# MKW01Z4 register map
File version: 1.6
Registers are 32-bit, read-write, reset 0x0 unless marked. A register's access mark holds for its fields unless they carry their own. Offsets are from the block's base; [hi:lo] are bit positions; {n}, {i} and the like mark numbered series; 'fields as' and 'values as' point back to an identical list.

## TPM0 — Timer/PWM Module
Base 0x40038000; register names take the prefix TPM0_
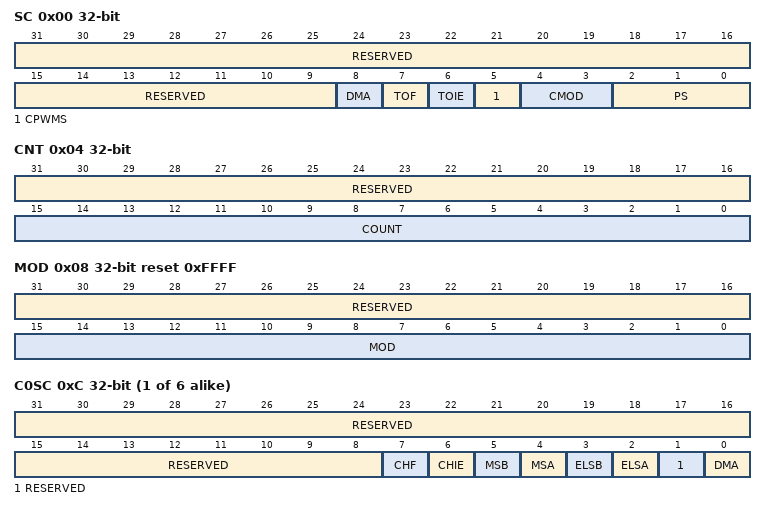
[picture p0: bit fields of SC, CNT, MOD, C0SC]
0x00 SC — Status and Control
  [31:9] RESERVED ro
  [8] DMA — DMA Enable
    0=Disables DMA transfers; 1=Enables DMA transfers
  [7] TOF — Timer Overflow Flag
    0=TPM counter has not overflowed; 1=TPM counter has overflowed
  [6] TOIE — Timer Overflow Interrupt Enable
    0=Disable TOF interrupts. Use software polling or DMA request.; 1=Enable TOF interrupts. An interrupt is generated when TOF equals one.
  [5] CPWMS — Center-Aligned PWM Select
    0=TPM counter operates in up counting mode; 1=TPM counter operates in up-down counting mode
  [4:3] CMOD — Clock Mode Selection
    0=TPM counter is disabled; 1=TPM counter increments on every TPM counter clock; 2=TPM counter increments on rising edge of TPM_EXTCLK synchronized to the TPM counter clock
  [2:0] PS — Prescale Factor Selection
    0=Divide by 1; 1=Divide by 2; 2=Divide by 4; 3=Divide by 8; 4=Divide by 16; 5=Divide by 32; 6=Divide by 64; 7=Divide by 128
0x04 CNT — Counter
  [31:16] RESERVED ro
  [15:0] COUNT — Counter value
0x08 MOD reset 0xFFFF — Modulo
  [31:16] RESERVED ro
  [15:0] MOD — Modulo value
{0xC+8i} C{i}SC (i=0..5) — Channel (n) Status and Control
  [31:8] RESERVED ro
  [7] CHF — Channel Flag
    0=No channel event has occurred; 1=A channel event has occurred
  [6] CHIE — Channel Interrupt Enable
    0=Disable channel interrupts; 1=Enable channel interrupts
  [5] MSB — Channel Mode Select
  [4] MSA — Channel Mode Select
  [3] ELSB — Edge or Level Select
  [2] ELSA — Edge or Level Select
  [1] RESERVED ro
  [0] DMA — DMA Enable
    0=Disable DMA transfers; 1=Enable DMA transfers
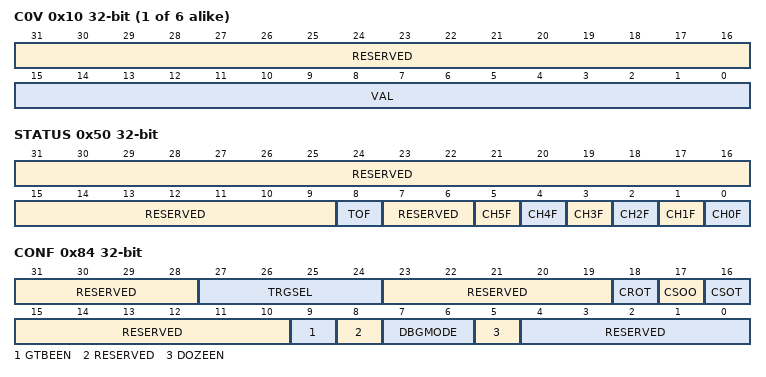
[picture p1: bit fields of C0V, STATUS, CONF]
{0x10+8i} C{i}V (i=0..5) — Channel (n) Value
  [31:16] RESERVED ro
  [15:0] VAL — Channel Value
0x50 STATUS — Capture and Compare Status
  [31:9] RESERVED ro
  [8] TOF — Timer Overflow Flag
    values as SC.TOF
  [7:6] RESERVED ro
  [n] CH{n}F (n=0..5) — Channel {n} Flag
    values as C0SC.CHF
0x84 CONF — Configuration
  [31:28] RESERVED ro
  [27:24] TRGSEL — Trigger Select
  [23:19] RESERVED ro
  [18] CROT — Counter Reload On Trigger
    0=Counter is not reloaded due to a rising edge on the selected input trigger; 1=Counter is reloaded when a rising edge is detected on the selected input trigger
  [17] CSOO — Counter Stop On Overflow
    0=TPM counter continues incrementing or decrementing after overflow; 1=TPM counter stops incrementing or decrementing after overflow
  [16] CSOT — Counter Start on Trigger
    0=TPM counter starts to increment immediately, once it is enabled; 1=TPM counter only starts to increment when it a rising edge on the selected input trigger is detected, after it has been enabled or after it has stopped due to overflow
  [15:10] RESERVED ro
  [9] GTBEEN — Global time base enable
    0=All channels use the internally generated TPM counter as their timebase; 1=All channels use an externally generated global timebase as their timebase
  [8] RESERVED ro
  [7:6] DBGMODE — Debug Mode
    0=TPM counter is paused and does not increment during debug mode. Trigger inputs and input capture events are also ignored.; 3=TPM counter continues in debug mode
  [5] DOZEEN — Doze Enable
    0=Internal TPM counter continues in Doze mode; 1=Internal TPM counter is paused and does not increment during Doze mode. Trigger inputs and input capture events are also ignored.
  [4:0] RESERVED ro

## TPM1 — Timer/PWM Module
Base 0x40039000; register names take the prefix TPM1_
Registers as TPM0, without C*SC, C*V; these are added or differ:
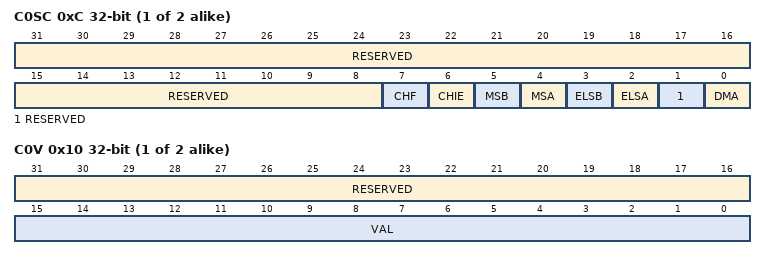
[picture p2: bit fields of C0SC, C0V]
{0xC+8i} C{i}SC (i=0..1) — Channel (n) Status and Control
  fields as TPM0.C0SC
{0x10+8i} C{i}V (i=0..1) — Channel (n) Value
  [31:16] RESERVED ro
  [15:0] VAL — Channel Value

## TPM2 — Timer/PWM Module
Base 0x4003A000; register names take the prefix TPM2_
Registers as TPM1.
